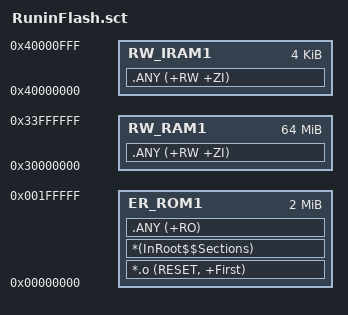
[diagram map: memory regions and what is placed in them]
; *************************************************************
; *** Scatter-Loading Description File generated by uVision ***
; *************************************************************
;Run in Flash

LR_ROM1 0x00000000         {    ; load region
  ER_ROM1 0x0000000 0x0200000  {  ; load address = execution address
   *.o (RESET, +First)
   *(InRoot$$Sections)
   .ANY (+RO)		 //所有的只读数据	，顺序链接	，括号里是条件
  }
  RW_RAM1 0x30000000 0x4000000  {  ; RW data
   .ANY (+RW +ZI)			  //所有的读写，以及零初始化区
  }
  RW_IRAM1 0x40000000 0x00001000  {
   .ANY (+RW +ZI)
  }
}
